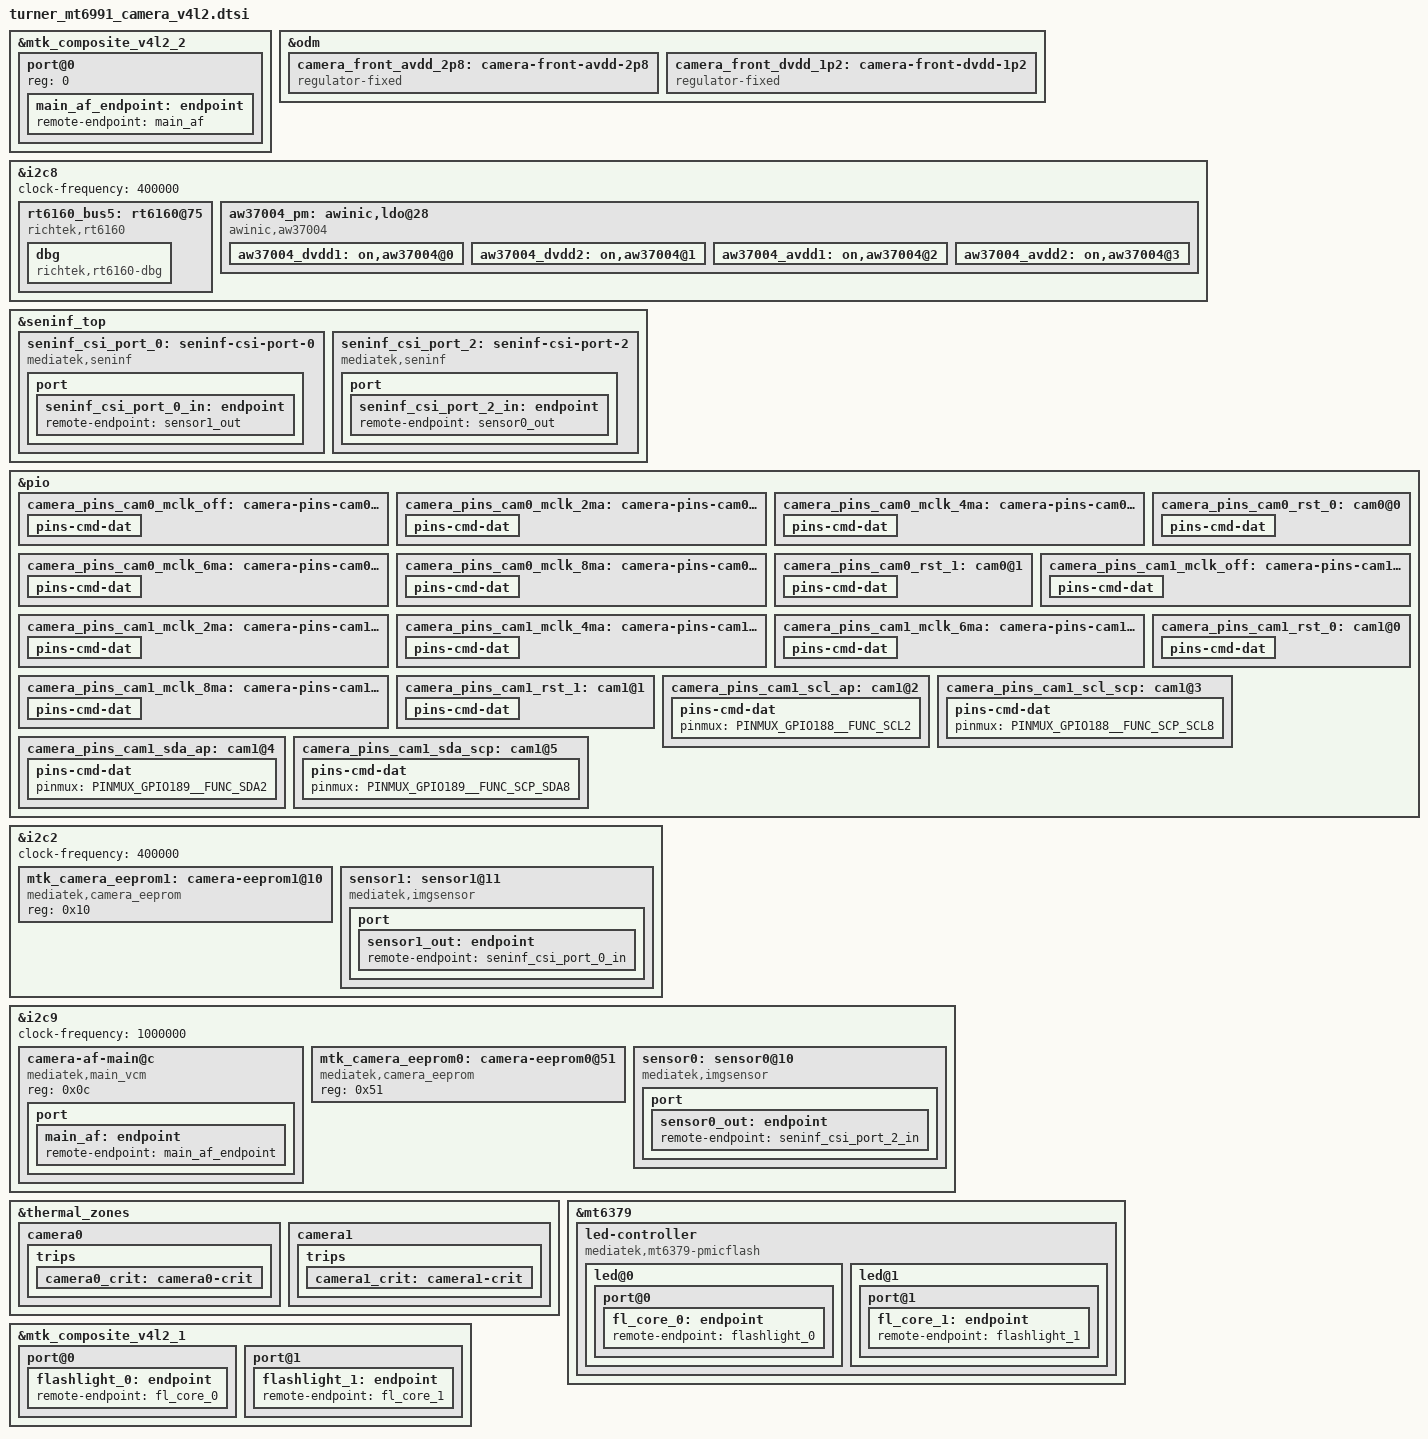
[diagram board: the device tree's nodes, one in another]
// SPDX-License-Identifier: GPL-2.0
/* Copyright (c) 2023 MediaTek Inc. */
#include <dt-bindings/clock/mt6991-clk.h>
#include <dt-bindings/leds/common.h>
#include <dt-bindings/mfd/mt6379.h>

&mtk_composite_v4l2_2 {
        #address-cells = <1>;
        #size-cells = <0>;
        port@0 {
                reg = <0>;
                main_af_endpoint: endpoint {
                        remote-endpoint = <&main_af>;
                };
        };
};

/* CAMERA GPIO fixed to regulator */
&odm {
	camera_front_avdd_2p8: camera-front-avdd-2p8 {
		compatible = "regulator-fixed";
		regulator-name = "camera-front-avdd-2p8";
		regulator-min-microvolt = <2800000>;
		regulator-max-microvolt = <2800000>;
		gpio = <&pio 93 0x0>;
		enable-active-high;
	};

	camera_front_dvdd_1p2: camera-front-dvdd-1p2 {
		compatible = "regulator-fixed";
		regulator-name = "camera-front-dvdd-1p2";
		regulator-min-microvolt = <1200000>;
		regulator-max-microvolt = <1200000>;
		gpio = <&pio 92 0x0>;
		enable-active-high;
	};
};

&i2c8 {
	clock-frequency = <400000>;
	status = "okay";

	rt6160_bus5: rt6160@75 {
		compatible = "richtek,rt6160";
		reg = <0x75>;
		//enable-gpios = <&gpio26 2 0>;
		regulator-name = "rt6160-buckboost";
		regulator-min-microvolt = <2025000>;
		regulator-max-microvolt = <5200000>;
		//regulator-always-on;

		dbg {
			compatible = "richtek,rt6160-dbg";
		};
	};

	aw37004_pm:awinic,ldo@28 {
		compatible = "awinic,aw37004";
		reg = <0x28>;
		//enable-gpio = <&gpio 226 0>;
		index = <0>;

		aw37004_dvdd1:on,aw37004@0{
			offset = /bits/ 16 <0x0000>;
			regulator-name ="dvdd1";
			regulator-min-microvolt = <600000>;
			regulator-max-microvolt = <2130000>;
			regulator-min-microamp = <1300000>;
			regulator-max-microamp = <1720000>;
			regulator-active-discharge = <1>;
			// regulator-always-on;
			init-voltage = <600000>;
			ilimit-ua = <1300000>;
		};

		aw37004_dvdd2:on,aw37004@1{
			offset = /bits/ 16 <0x0001>;
			regulator-name ="dvdd2";
			regulator-min-microvolt = <600000>;
			regulator-max-microvolt = <2130000>;
			regulator-min-microamp = <1300000>;
			regulator-max-microamp = <1720000>;
			regulator-active-discharge = <1>;
			// regulator-always-on;
			init-voltage = <600000>;
			ilimit-ua = <1300000>;
		};

		aw37004_avdd1:on,aw37004@2{
			offset = /bits/ 16 <0x0002>;
			regulator-name ="avdd1";
			regulator-min-microvolt = <1200000>;
			regulator-max-microvolt = <4387500>;
			regulator-min-microamp = <480000>;
			regulator-max-microamp = <900000>;
			regulator-active-discharge = <1>;
			// regulator-always-on;
			init-voltage = <1200000>;
			ilimit-ua = <480000>;
		};

		aw37004_avdd2:on,aw37004@3{
			offset = /bits/ 16 <0x0003>;
			regulator-name ="avdd2";
			regulator-min-microvolt = <1200000>;
			regulator-max-microvolt = <4387500>;
			regulator-min-microamp = <480000>;
			regulator-max-microamp = <900000>;
			regulator-active-discharge = <1>;
			// regulator-always-on;
			init-voltage = <1200000>;
			ilimit-ua = <480000>;
		};
	};
};

&seninf_top {
		seninf_csi_port_0: seninf-csi-port-0 {
			compatible = "mediatek,seninf";
			csi-port = "0";

			nvmem-cells = <&csi_efuse0>;
			nvmem-cell-names = "rg_csi";

			port {
				seninf_csi_port_0_in: endpoint {
					remote-endpoint = <&sensor1_out>;
				};
			};
		};

		seninf_csi_port_2: seninf-csi-port-2 {
			compatible = "mediatek,seninf";
			csi-port = "2";

			nvmem-cells = <&csi_efuse2>;
			nvmem-cell-names = "rg_csi";

			port {
				seninf_csi_port_2_in: endpoint {
					remote-endpoint = <&sensor0_out>;
				};
			};
		};
};

/* CAMERA GPIO standardization */
&pio {
	camera_pins_cam0_mclk_off: camera-pins-cam0-mclk-off {
		pins-cmd-dat {
			pinmux = <PINMUX_GPIO196__FUNC_GPIO196>;
			drive-strength = <1>;
		};
	};
	camera_pins_cam0_mclk_2ma: camera-pins-cam0-mclk-2ma {
		pins-cmd-dat {
			pinmux = <PINMUX_GPIO196__FUNC_CMMCLK3>;
			drive-strength = <0>;
		};
	};
	camera_pins_cam0_mclk_4ma: camera-pins-cam0-mclk-4ma {
		pins-cmd-dat {
			pinmux = <PINMUX_GPIO196__FUNC_CMMCLK3>;
			drive-strength = <1>;
		};
	};
	camera_pins_cam0_mclk_6ma: camera-pins-cam0-mclk-6ma {
		pins-cmd-dat {
			pinmux = <PINMUX_GPIO196__FUNC_CMMCLK3>;
			drive-strength = <2>;
		};
	};
	camera_pins_cam0_mclk_8ma: camera-pins-cam0-mclk-8ma {
		pins-cmd-dat {
			pinmux = <PINMUX_GPIO196__FUNC_CMMCLK3>;
			drive-strength = <3>;
		};
	};
	camera_pins_cam0_rst_0: cam0@0 {
		pins-cmd-dat {
			pinmux = <PINMUX_GPIO197__FUNC_GPIO197>;
			drive-strength = <0>;
			output-low;
		};
	};
	camera_pins_cam0_rst_1: cam0@1 {
		pins-cmd-dat {
			pinmux = <PINMUX_GPIO197__FUNC_GPIO197>;
			drive-strength = <1>;
			output-high;
		};
	};
	camera_pins_cam1_mclk_off: camera-pins-cam1-mclk-off {
		pins-cmd-dat {
			pinmux = <PINMUX_GPIO79__FUNC_GPIO79>;
			drive-strength = <1>;
		};
	};
	camera_pins_cam1_mclk_2ma: camera-pins-cam1-mclk-2ma {
		pins-cmd-dat {
			pinmux = <PINMUX_GPIO79__FUNC_CMMCLK0>;
			drive-strength = <0>;
		};
	};
	camera_pins_cam1_mclk_4ma: camera-pins-cam1-mclk-4ma {
		pins-cmd-dat {
			pinmux = <PINMUX_GPIO79__FUNC_CMMCLK0>;
			drive-strength = <1>;
		};
	};
	camera_pins_cam1_mclk_6ma: camera-pins-cam1-mclk-6ma {
		pins-cmd-dat {
			pinmux = <PINMUX_GPIO79__FUNC_CMMCLK0>;
			drive-strength = <2>;
		};
	};
	camera_pins_cam1_mclk_8ma: camera-pins-cam1-mclk-8ma {
		pins-cmd-dat {
			pinmux = <PINMUX_GPIO79__FUNC_CMMCLK0>;
			drive-strength = <3>;
		};
	};
	camera_pins_cam1_rst_0: cam1@0 {
		pins-cmd-dat {
			pinmux = <PINMUX_GPIO186__FUNC_GPIO186>;
			slew-rate = <1>;
			output-low;
		};
	};
	camera_pins_cam1_rst_1: cam1@1 {
		pins-cmd-dat {
			pinmux = <PINMUX_GPIO186__FUNC_GPIO186>;
			slew-rate = <1>;
			output-high;
		};
	};
	camera_pins_cam1_scl_ap: cam1@2 {
		pins-cmd-dat {
			pinmux = <PINMUX_GPIO188__FUNC_SCL2>;
		};
	};
	camera_pins_cam1_scl_scp: cam1@3 {
		pins-cmd-dat {
			pinmux = <PINMUX_GPIO188__FUNC_SCP_SCL8>;
		};
	};
	camera_pins_cam1_sda_ap: cam1@4 {
		pins-cmd-dat {
			pinmux = <PINMUX_GPIO189__FUNC_SDA2>;
		};
	};
	camera_pins_cam1_sda_scp: cam1@5 {
		pins-cmd-dat {
			pinmux = <PINMUX_GPIO189__FUNC_SCP_SDA8>;
		};
	};
};
/* CAMERA GPIO end */

&i2c2 {
	status = "okay";
	clock-frequency = <400000>;

	mtk_camera_eeprom1:camera-eeprom1@10 {
		compatible = "mediatek,camera_eeprom";
		reg = <0x10>;
		status = "okay";
	};

	sensor1: sensor1@11 {
		compatible = "mediatek,imgsensor";
		sensor-names = "turnerov08f10front_mipi_raw";
		reg = <0x11>;

		#thermal-sensor-cells = <0>;

		pinctrl-names = "mclk1_off",
				"mclk1_2mA",
				"mclk1_4mA",
				"mclk1_6mA",
				"mclk1_8mA",
				"rst_low",
				"rst_high",
				"scl_ap",
				"scl_scp",
				"sda_ap",
				"sda_scp";
		pinctrl-0 = <&camera_pins_cam1_mclk_off>;
		pinctrl-1 = <&camera_pins_cam1_mclk_2ma>;
		pinctrl-2 = <&camera_pins_cam1_mclk_4ma>;
		pinctrl-3 = <&camera_pins_cam1_mclk_6ma>;
		pinctrl-4 = <&camera_pins_cam1_mclk_8ma>;
		pinctrl-5 = <&camera_pins_cam1_rst_0>;
		pinctrl-6 = <&camera_pins_cam1_rst_1>;
		pinctrl-7 = <&camera_pins_cam1_scl_ap>;
		pinctrl-8 = <&camera_pins_cam1_scl_scp>;
		pinctrl-9 = <&camera_pins_cam1_sda_ap>;
		pinctrl-10 = <&camera_pins_cam1_sda_scp>;

		avdd-supply = <&camera_front_avdd_2p8>;
		avdd1-supply = <&rt6160_bus5>;
		dvdd-supply = <&mt6373_vbuck8>;
		dovdd-supply = <&mt6373_vrfio18_aif>;
		dvdd1-supply = <&camera_front_dvdd_1p2>;

		clocks = <&cksys_clk CLK_CK_UNIVPLL_192M_D32>,
			<&cksys_clk CLK_CK_UNIVPLL_192M_D16>,
			<&cksys_clk CLK_CK_F26M_CK_D2>,
			<&cksys_clk CLK_CK_UNIVPLL_192M_D10>,
			<&cksys_clk CLK_CK_UNIVPLL_192M_D8>,
			<&cksys_clk CLK_CK_UNIVPLL_D6_D16>,
			<&cksys_clk CLK_CK_OSC3>,
			<&cksys_clk CLK_CK_UNIVPLL_D6_D8>,
			<&vlp_cksys_clk CLK_VLP_CK_CAMTG0_SEL>;
		clock-names = "clk1_6", "clk1_12", "clk1_13", "clk1_19.2", "clk1_24", "clk1_26", "clk1_26_ulposc", "clk1_52", "clk1_mclk1";

		status = "okay";
		port {
			sensor1_out: endpoint {
				remote-endpoint = <&seninf_csi_port_0_in>;
			};
		};
	};
};

&i2c9 {
	status = "okay";
	clock-frequency = <1000000>;

	camera-af-main@c {
                compatible = "mediatek,main_vcm";
                reg = <0x0c>;
                port {
                        main_af: endpoint {
                                remote-endpoint = <&main_af_endpoint>;
                        };
                };
        };

	mtk_camera_eeprom0:camera-eeprom0@51 {
		compatible = "mediatek,camera_eeprom";
		reg = <0x51>;
		status = "okay";
	};

	sensor0: sensor0@10 {
		compatible = "mediatek,imgsensor";
		sensor-names = "turnerov13b10wide_mipi_raw";
		reg = <0x10>;

		pinctrl-names = "mclk_off",
				"mclk_2mA",
				"mclk_4mA",
				"mclk_6mA",
				"mclk_8mA",
				"rst_low",
				"rst_high";
		pinctrl-0 = <&camera_pins_cam0_mclk_off>;
		pinctrl-1 = <&camera_pins_cam0_mclk_2ma>;
		pinctrl-2 = <&camera_pins_cam0_mclk_4ma>;
		pinctrl-3 = <&camera_pins_cam0_mclk_6ma>;
		pinctrl-4 = <&camera_pins_cam0_mclk_8ma>;
		pinctrl-5 = <&camera_pins_cam0_rst_0>;
		pinctrl-6 = <&camera_pins_cam0_rst_1>;

		avdd-supply = <&aw37004_avdd2>;
		dvdd-supply = <&aw37004_dvdd1>;
		dvdd1-supply = <&mt6373_vbuck8>;
		avdd1-supply = <&rt6160_bus5>;
		dovdd-supply = <&mt6373_vrfio18_aif>;
		afvdd-supply = <&aw37004_avdd1>;


		clocks = <&cksys_clk CLK_CK_UNIVPLL_192M_D32>,
			<&cksys_clk CLK_CK_UNIVPLL_192M_D16>,
			<&cksys_clk CLK_CK_F26M_CK_D2>,
			<&cksys_clk CLK_CK_UNIVPLL_192M_D10>,
			<&cksys_clk CLK_CK_UNIVPLL_192M_D8>,
			<&cksys_clk CLK_CK_UNIVPLL_D6_D16>,
			<&cksys_clk CLK_CK_OSC3>,
			<&cksys_clk CLK_CK_UNIVPLL_D6_D8>,
			<&vlp_cksys_clk CLK_VLP_CK_CAMTG3_SEL>;
		clock-names = "6", "12", "13", "19.2", "24", "26", "26_ulposc", "52", "mclk";

		status = "okay";
		port {
			sensor0_out: endpoint {
				remote-endpoint = <&seninf_csi_port_2_in>;
			};
		};
	};
};

&thermal_zones {
	camera0: camera0 {
		polling-delay = <0>; /* milliseconds */
		polling-delay-passive = <0>; /* milliseconds */
		thermal-sensors = <&sensor0>;
		trips {
			camera0_crit: camera0-crit {
				temperature = <120000>;
				hysteresis = <2000>;
				type = "passive";
			};
		};
	};
	camera1: camera1 {
		polling-delay = <0>; /* milliseconds */
		polling-delay-passive = <0>; /* milliseconds */
		thermal-sensors = <&sensor1>;
		trips {
			camera1_crit: camera1-crit {
				temperature = <120000>;
				hysteresis = <2000>;
				type = "passive";
			};
		};
	};
};


	&mt6379{
		led-controller {
			compatible = "mediatek,mt6379-pmicflash";
			#address-cells = <1>;
			#size-cells = <0>;
			interrupts = <MT6379_EVT_FLED_LVF> , <MT6379_EVT_FL_BUBO_VIN_THRO>,
				     <MT6379_EVT_FL_THERMAL_THRO>, <MT6379_EVT_FL_BUBO_IL_THRO>,
				     <MT6379_EVT_FLED3_SHORT>, <MT6379_EVT_FLED2_SHORT>,
				     <MT6379_EVT_FLED1_SHORT>;
			interrupt-names = "fled_lvf", "fled_bubo_vin_thro",
					  "fled_thermal_thro", "fled_bubo_il_thro",
					  "fled3_short", "fled2_short",
					  "fled1_short";
			led@0 {
				reg = <0>;
				function = LED_FUNCTION_FLASH;
				color = <LED_COLOR_ID_WHITE>;
				function-enumerator = <1>;
				led-max-microamp = <400000>;
				flash-max-microamp = <1500000>;
				type = <0>;
				ct = <0>;
				part = <0>;
				port@0 {
					fl_core_0: endpoint {
						remote-endpoint = <&flashlight_0>;
					};
				};
			};
			led@1 {
				reg = <1>;
				function = LED_FUNCTION_FLASH;
				color = <LED_COLOR_ID_WHITE>;
				function-enumerator = <2>;
				led-max-microamp = <400000>;
				flash-max-microamp = <1500000>;
				type = <0>;
				ct = <1>;
				part = <0>;
				port@1 {
					fl_core_1: endpoint {
						remote-endpoint = <&flashlight_1>;
					};
				};
			};
		};
	};


&mtk_composite_v4l2_1 {
	port@0 {
			flashlight_0: endpoint {
				remote-endpoint = <&fl_core_0>;
			};
	};
	port@1 {
			flashlight_1: endpoint {
				remote-endpoint = <&fl_core_1>;
			};
	};
};
